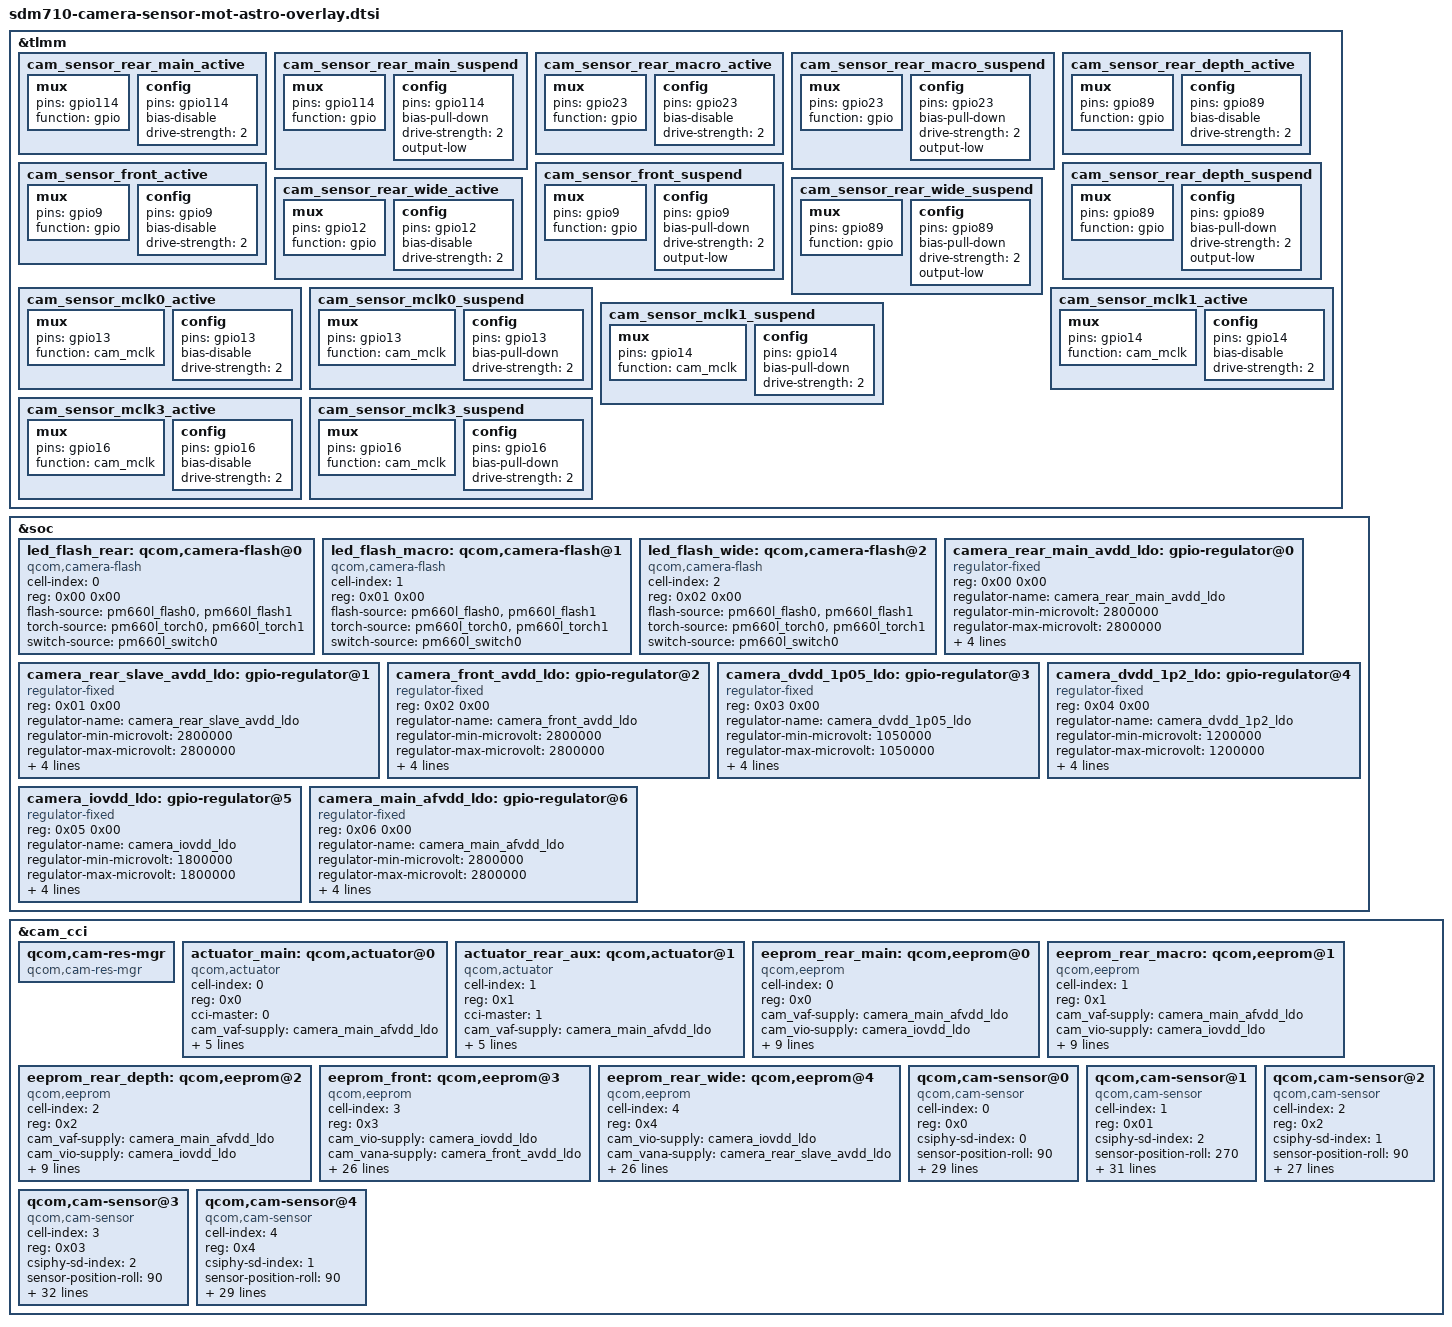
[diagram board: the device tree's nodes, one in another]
/*
 * Copyright (c) 2016-2018, The Linux Foundation. All rights reserved.
 *
 * This program is free software; you can redistribute it and/or modify
 * it under the terms of the GNU General Public License version 2 and
 * only version 2 as published by the Free Software Foundation.
 *
 * This program is distributed in the hope that it will be useful,
 * but WITHOUT ANY WARRANTY; without even the implied warranty of
 * MERCHANTABILITY or FITNESS FOR A PARTICULAR PURPOSE.  See the
 * GNU General Public License for more details.
 */

&tlmm {
	/*REAR_MAIN:CAM0_RST_N*/
	cam_sensor_rear_main_active: cam_sensor_rear_main_active {
		/* MAIN RESET active*/
		mux {
			pins = "gpio114";
			function = "gpio";
		};

		config {
			pins = "gpio114";
			bias-disable; /* No PULL */
			drive-strength = <2>; /* 2 MA */
		};
	};

	cam_sensor_rear_main_suspend: cam_sensor_rear_main_suspend {
		/* MAIN RESET suspend*/
		mux {
			pins = "gpio114";
			function = "gpio";
		};

		config {
			pins = "gpio114";
			bias-pull-down; /* PULL DOWN */
			drive-strength = <2>; /* 2 MA */
			output-low;
		};
	};
	/*MACRO:CAM1_RST_N*/
	cam_sensor_rear_macro_active: cam_sensor_rear_macro_active {
		/* MACRO RESET active*/
		mux {
			pins = "gpio23";
			function = "gpio";
		};

		config {
			pins = "gpio23";
			bias-disable; /* No PULL */
			drive-strength = <2>; /* 2 MA */
		};
	};

	cam_sensor_rear_macro_suspend: cam_sensor_rear_macro_suspend {
		/* MAIN RESET suspend*/
		mux {
			pins = "gpio23";
			function = "gpio";
		};

		config {
			pins = "gpio23";
			bias-pull-down; /* PULL DOWN */
			drive-strength = <2>; /* 2 MA */
			output-low;
		};
	};

/*depth:CAM3_RST_N*/
	cam_sensor_rear_depth_active: cam_sensor_rear_depth_active {
		/* MACRO RESET active*/
		mux {
			pins = "gpio89";
			function = "gpio";
		};

		config {
			pins = "gpio89";
			bias-disable; /* No PULL */
			drive-strength = <2>; /* 2 MA */
		};
	};

	cam_sensor_rear_depth_suspend: cam_sensor_rear_depth_suspend {
		/* MAIN RESET suspend*/
		mux {
			pins = "gpio89";
			function = "gpio";
		};

		config {
			pins = "gpio89";
			bias-pull-down; /* PULL DOWN */
			drive-strength = <2>; /* 2 MA */
			output-low;
		};
	};

/*front s5k4h7 CAM2_RST_N*/
 cam_sensor_front_active: cam_sensor_front_active {
		/* MACRO RESET active*/
		mux {
			pins = "gpio9";
			function = "gpio";
		};

		config {
			pins = "gpio9";
			bias-disable; /* No PULL */
			drive-strength = <2>; /* 2 MA */
		};
	};

	cam_sensor_front_suspend: cam_sensor_front_suspend {
		/* MAIN RESET suspend*/
		mux {
			pins = "gpio9";
			function = "gpio";
		};

		config {
			pins = "gpio9";
			bias-pull-down; /* PULL DOWN */
			drive-strength = <2>; /* 2 MA */
			output-low;
		};
	};
/*rear wide s5k4h7 CAM4_RST_N */
cam_sensor_rear_wide_active: cam_sensor_rear_wide_active {
		/* MACRO RESET active*/
		mux {
			pins = "gpio12";
			function = "gpio";
		};

		config {
			pins = "gpio12";
			bias-disable; /* No PULL */
			drive-strength = <2>; /* 2 MA */
		};
	};

	cam_sensor_rear_wide_suspend: cam_sensor_rear_wide_suspend {
		/* MAIN RESET suspend*/
		mux {
			pins = "gpio89";
			function = "gpio";
		};

		config {
			pins = "gpio89";
			bias-pull-down; /* PULL DOWN */
			drive-strength = <2>; /* 2 MA */
			output-low;
		};
	};

	cam_sensor_mclk0_active: cam_sensor_mclk0_active {
		/* MCLK0 */
		mux {
			pins = "gpio13";
			function = "cam_mclk";
		};

		config {
			pins = "gpio13";
			bias-disable; /* No PULL */
			drive-strength = <2>; /* 2 MA */
		};
	};

	cam_sensor_mclk0_suspend: cam_sensor_mclk0_suspend {
		/* MCLK0 */
		mux {
			pins = "gpio13";
			function = "cam_mclk";
		};

		config {
			pins = "gpio13";
			bias-pull-down; /* PULL DOWN */
			drive-strength = <2>; /* 2 MA */
		};
	};

	cam_sensor_mclk1_active: cam_sensor_mclk1_active {
		/* MCLK1 */
		mux {
			pins = "gpio14";
			function = "cam_mclk";
		};

		config {
			pins = "gpio14";
			bias-disable; /* No PULL */
			drive-strength = <2>; /* 2 MA */
		};
	};

	cam_sensor_mclk1_suspend: cam_sensor_mclk1_suspend {
		/* MCLK0 */
		mux {
			pins = "gpio14";
			function = "cam_mclk";
		};

		config {
			pins = "gpio14";
			bias-pull-down; /* PULL DOWN */
			drive-strength = <2>; /* 2 MA */
		};
	};

	cam_sensor_mclk3_active: cam_sensor_mclk3_active {
		/* MCLK1 */
		mux {
			pins = "gpio16";
			function = "cam_mclk";
		};

		config {
			pins = "gpio16";
			bias-disable; /* No PULL */
			drive-strength = <2>; /* 2 MA */
		};
	};

	cam_sensor_mclk3_suspend: cam_sensor_mclk3_suspend {
		/* MCLK0 */
		mux {
			pins = "gpio16";
			function = "cam_mclk";
		};

		config {
			pins = "gpio16";
			bias-pull-down; /* PULL DOWN */
			drive-strength = <2>; /* 2 MA */
		};
	};
};

&soc {
	led_flash_rear: qcom,camera-flash@0 {
		cell-index = <0>;
		reg = <0x00 0x00>;
		compatible = "qcom,camera-flash";
		flash-source = <&pm660l_flash0 &pm660l_flash1>;
		torch-source = <&pm660l_torch0 &pm660l_torch1>;
		switch-source = <&pm660l_switch0>;
		status = "ok";
	};
	led_flash_macro: qcom,camera-flash@1 {
		cell-index = <1>;
		reg = <0x01 0x00>;
		compatible = "qcom,camera-flash";
		flash-source = <&pm660l_flash0 &pm660l_flash1>;
		torch-source = <&pm660l_torch0 &pm660l_torch1>;
		switch-source = <&pm660l_switch0>;
		status = "ok";
	};
	led_flash_wide: qcom,camera-flash@2 {
		cell-index = <2>;
		reg = <0x02 0x00>;
		compatible = "qcom,camera-flash";
		flash-source = <&pm660l_flash0 &pm660l_flash1>;
		torch-source = <&pm660l_torch0 &pm660l_torch1>;
		switch-source = <&pm660l_switch0>;
		status = "ok";
	};
	/*avdd*/
	camera_rear_main_avdd_ldo: gpio-regulator@0 {
		compatible = "regulator-fixed";
		reg = <0x00 0x00>;
		regulator-name = "camera_rear_main_avdd_ldo";
		regulator-min-microvolt = <2800000>;
		regulator-max-microvolt = <2800000>;
		regulator-enable-ramp-delay = <233>;
		enable-active-high;
		gpio = <&tlmm 11 0>;
		vin-supply = <&pm660l_bob>;
	};

	camera_rear_slave_avdd_ldo: gpio-regulator@1 {
		compatible = "regulator-fixed";
		reg = <0x01 0x00>;
		regulator-name = "camera_rear_slave_avdd_ldo";
		regulator-min-microvolt = <2800000>;
		regulator-max-microvolt = <2800000>;
		regulator-enable-ramp-delay = <233>;
		enable-active-high;
		gpio = <&tlmm 76 0>;
		vin-supply = <&pm660l_bob>;
	};
	camera_front_avdd_ldo: gpio-regulator@2 {
		compatible = "regulator-fixed";
		reg = <0x02 0x00>;
		regulator-name = "camera_front_avdd_ldo";
		regulator-min-microvolt = <2800000>;
		regulator-max-microvolt = <2800000>;
		regulator-enable-ramp-delay = <233>;
		enable-active-high;
		gpio = <&tlmm 77 0>;
		vin-supply = <&pm660l_bob>;
	};
	/*dvdd*/
	camera_dvdd_1p05_ldo: gpio-regulator@3 {
		compatible = "regulator-fixed";
		reg = <0x03 0x00>;
		regulator-name = "camera_dvdd_1p05_ldo";
		regulator-min-microvolt = <1050000>;
		regulator-max-microvolt = <1050000>;
		regulator-enable-ramp-delay = <233>;
		enable-active-high;
		gpio = <&tlmm 21 0>;
		vin-supply = <&pm660_s6>;
	};
	camera_dvdd_1p2_ldo: gpio-regulator@4 {
		compatible = "regulator-fixed";
		reg = <0x04 0x00>;
		regulator-name = "camera_dvdd_1p2_ldo";
		regulator-min-microvolt = <1200000>;
		regulator-max-microvolt = <1200000>;
		regulator-enable-ramp-delay = <233>;
		enable-active-high;
		gpio = <&pm660l_gpios 4 0>;
		vin-supply = <&pm660_s6>;
	};

//dovdd
	camera_iovdd_ldo: gpio-regulator@5 {
		compatible = "regulator-fixed";
		reg = <0x05 0x00>;
		regulator-name = "camera_iovdd_ldo";
		regulator-min-microvolt = <1800000>;
		regulator-max-microvolt = <1800000>;
		regulator-enable-ramp-delay = <233>;
		enable-active-high;
		gpio = <&tlmm 143 0>;
		vin-supply = <&pm660_s4>;
	};

//actuator:
	camera_main_afvdd_ldo: gpio-regulator@6 {
		compatible = "regulator-fixed";
		reg = <0x06 0x00>;
		regulator-name = "camera_main_afvdd_ldo";
		regulator-min-microvolt = <2800000>;
		regulator-max-microvolt = <2800000>;
		regulator-enable-ramp-delay = <233>;
		enable-active-high;
		gpio = <&tlmm 26 0>;
		vin-supply = <&pm660l_bob>;
	};
};

&cam_cci {
	qcom,cam-res-mgr {
		compatible = "qcom,cam-res-mgr";
		status = "ok";
    };
	actuator_main: qcom,actuator@0 {
		cell-index = <0>;
		reg = <0x0>;
		compatible = "qcom,actuator";
		cci-master = <0>;
		cam_vaf-supply = <&camera_main_afvdd_ldo>;
		regulator-names = "cam_vaf";
		rgltr-cntrl-support;
		rgltr-min-voltage = <2800000>;
		rgltr-max-voltage = <2800000>;
		rgltr-load-current = <0>;
	};
	actuator_rear_aux: qcom,actuator@1 {
		cell-index = <1>;
		reg = <0x1>;
		compatible = "qcom,actuator";
		cci-master = <1>;
		cam_vaf-supply = <&camera_main_afvdd_ldo>;
		regulator-names = "cam_vaf";
		rgltr-cntrl-support;
		rgltr-min-voltage = <2800000>;
		rgltr-max-voltage = <2800000>;
		rgltr-load-current = <0>;
	};
//eeprom for s5kgm1
	eeprom_rear_main: qcom,eeprom@0 {
		cell-index = <0>;
		reg = <0x0>;
		compatible = "qcom,eeprom";
		cam_vaf-supply = <&camera_main_afvdd_ldo>;
		cam_vio-supply = <&camera_iovdd_ldo>;
		regulator-names = "cam_vaf", "cam_vio";
		rgltr-cntrl-support;
		rgltr-min-voltage = <2800000 1800000>;
		rgltr-max-voltage = <2800000 1800000>;
		rgltr-load-current = <0 0>;
		cci-master = <0>;
		status = "ok";
		clocks = <&clock_camcc CAM_CC_MCLK0_CLK>;
		clock-names = "cam_clk";
		clock-cntl-level = "turbo";
		clock-rates = <24000000>;
	};
//eeprom for s5k5e9
	eeprom_rear_macro: qcom,eeprom@1 {
		cell-index = <1>;
		reg = <0x1>;
		compatible = "qcom,eeprom";
		cam_vaf-supply = <&camera_main_afvdd_ldo>;
		cam_vio-supply = <&camera_iovdd_ldo>;
		regulator-names = "cam_vaf", "cam_vio";
		rgltr-cntrl-support;
		rgltr-min-voltage = <2800000 1800000>;
		rgltr-max-voltage = <2800000 1800000>;
		rgltr-load-current = <0 0>;
		cci-master = <1>;
		status = "ok";
		clocks = <&clock_camcc CAM_CC_MCLK1_CLK>;
		clock-names = "cam_clk";
		clock-cntl-level = "turbo";
		clock-rates = <24000000>;
	};
//eeprom for ov2180
	eeprom_rear_depth: qcom,eeprom@2 {
		cell-index = <2>;
		reg = <0x2>;
		compatible = "qcom,eeprom";
		cam_vaf-supply = <&camera_main_afvdd_ldo>;
		cam_vio-supply = <&camera_iovdd_ldo>;
		regulator-names = "cam_vaf", "cam_vio";
		rgltr-cntrl-support;
		rgltr-min-voltage = <2800000 1800000>;
		rgltr-max-voltage = <2800000 1800000>;
		rgltr-load-current = <0 0>;
		cci-master = <1>;
		status = "ok";
		clocks = <&clock_camcc CAM_CC_MCLK1_CLK>;
		clock-names = "cam_clk";
		clock-cntl-level = "turbo";
		clock-rates = <24000000>;
	};
//eeprom for front s5k4h7
	eeprom_front: qcom,eeprom@3 {
		cell-index = <3>;
		reg = <0x3>;
		compatible = "qcom,eeprom";
		cam_vio-supply = <&camera_iovdd_ldo>;
		cam_vana-supply = <&camera_front_avdd_ldo>;
		cam_vdig-supply = <&camera_dvdd_1p2_ldo>;
		cam_clk-supply = <&titan_top_gdsc>;
		regulator-names = "cam_vio", "cam_vana", "cam_vdig",
			"cam_clk";
		rgltr-cntrl-support;
		rgltr-min-voltage = <1800000 2800000 1200000 0>;
		rgltr-max-voltage = <1800000 2800000 1200000 0>;
		rgltr-load-current = <0 80000 120000 0>;
		gpio-no-mux = <0>;
		pinctrl-names = "cam_default", "cam_suspend";
		pinctrl-0 = <&cam_sensor_mclk3_active
				 &cam_sensor_front_active>;
		pinctrl-1 = <&cam_sensor_mclk3_suspend
				 &cam_sensor_front_suspend>;
		gpios = <&tlmm 16 0>,
				<&tlmm 9  0>,
				<&tlmm 24 0>,
				<&tlmm 25 0>;
		gpio-reset = <1>;
		gpio-custom1 = <2>;
		gpio-custom2 = <3>;
		gpio-req-tbl-num = <0 1 2 3>;
		gpio-req-tbl-flags = <1 0 0 0>;
		gpio-req-tbl-label = "CAMIF_MCLK3",
			"CAM_RESET2","CAM_GPIO_EN","CAM_GPIO_SEL";
		sensor-mode = <0>;
		cci-master = <0>;
		status = "ok";
		clocks = <&clock_camcc CAM_CC_MCLK3_CLK>;
		clock-names = "cam_clk";
		clock-cntl-level = "turbo";
		clock-rates = <24000000>;
	};
//eeprom for rear s5k4h7
	eeprom_rear_wide: qcom,eeprom@4 {
		cell-index = <4>;
		reg = <0x4>;
		compatible = "qcom,eeprom";
		cam_vio-supply = <&camera_iovdd_ldo>;
		cam_vana-supply = <&camera_rear_slave_avdd_ldo>;
		cam_vdig-supply = <&camera_dvdd_1p2_ldo>;
		cam_clk-supply = <&titan_top_gdsc>;
		regulator-names = "cam_vio", "cam_vana", "cam_vdig",
			"cam_clk";
		rgltr-cntrl-support;
		rgltr-min-voltage = <1800000 2800000 1200000 0>;
		rgltr-max-voltage = <1800000 2800000 1200000 0>;
		rgltr-load-current = <0 80000 120000 0>;
		gpio-no-mux = <0>;
		pinctrl-names = "cam_default", "cam_suspend";
		pinctrl-0 = <&cam_sensor_mclk3_active
				 &cam_sensor_rear_wide_active>;
		pinctrl-1 = <&cam_sensor_mclk3_suspend
				 &cam_sensor_rear_wide_suspend>;
		gpios = <&tlmm 16 0>,
				<&tlmm 12 0>,
				<&tlmm 24 0>,
				<&tlmm 25 0>;
		gpio-reset = <1>;
		gpio-custom1 = <2>;
		gpio-custom2 = <3>;
		gpio-req-tbl-num = <0 1 2 3>;
		gpio-req-tbl-flags = <1 0 0 0>;
		gpio-req-tbl-label = "CAMIF_MCLK3",
			"CAM_RESET4","CAM_GPIO_EN","CAM_GPIO_SEL";
		sensor-mode = <0>;
		cci-master = <1>;
		status = "ok";
		clocks = <&clock_camcc CAM_CC_MCLK3_CLK>;
		clock-names = "cam_clk";
		clock-cntl-level = "turbo";
		clock-rates = <24000000>;
	};

	qcom,cam-sensor@0 {
		cell-index = <0>;
		compatible = "qcom,cam-sensor";
		reg = <0x0>;
		csiphy-sd-index = <0>;
		sensor-position-roll = <90>;
		sensor-position-pitch = <0>;
		sensor-position-yaw = <180>;
		led-flash-src = <&led_flash_rear>;
		actuator-src = <&actuator_main>;
		eeprom-src = <&eeprom_rear_main>;
		cam_vio-supply = <&camera_iovdd_ldo>;
		cam_vana-supply = <&camera_rear_main_avdd_ldo>;
		cam_vdig-supply = <&camera_dvdd_1p05_ldo>;
		cam_clk-supply = <&titan_top_gdsc>;
		regulator-names = "cam_vio", "cam_vana", "cam_vdig", "cam_clk";
		rgltr-cntrl-support;
		rgltr-min-voltage = <1800000 2800000 1050000 0>;
		rgltr-max-voltage = <1800000 2800000 1050000 0>;
		rgltr-load-current = <0 80000 105000 0>;
		gpio-no-mux = <0>;
		pinctrl-names = "cam_default", "cam_suspend";
		pinctrl-0 = <&cam_sensor_mclk0_active
				&cam_sensor_rear_main_active>;
		pinctrl-1 = <&cam_sensor_mclk0_suspend
				&cam_sensor_rear_main_suspend>;
		gpios = <&tlmm 13 0>,
			<&tlmm 114 0>;
		gpio-reset = <1>;
		gpio-req-tbl-num = <0 1>;
		gpio-req-tbl-flags = <1 0>;
		gpio-req-tbl-label = "CAMIF_MCLK0",
					"CAM_RESET0";
		cci-master = <0>;
		status = "ok";
		clocks = <&clock_camcc CAM_CC_MCLK0_CLK>;
		clock-names = "cam_clk";
		clock-cntl-level = "turbo";
		clock-rates = <24000000>;
	};

/*8M s5k4h7  front*/
	qcom,cam-sensor@1 {
		cell-index = <1>;
		compatible = "qcom,cam-sensor";
		reg = <0x01>;
		csiphy-sd-index = <2>;
		sensor-position-roll = <270>;
		sensor-position-pitch = <0>;
		sensor-position-yaw = <0>;
		eeprom-src = <&eeprom_front>;
		cam_vio-supply = <&camera_iovdd_ldo>;
		cam_vana-supply = <&camera_front_avdd_ldo>;
		cam_vdig-supply = <&camera_dvdd_1p2_ldo>;
		cam_clk-supply = <&titan_top_gdsc>;
		regulator-names = "cam_vio", "cam_vana", "cam_vdig",
			"cam_clk";
		rgltr-cntrl-support;
		rgltr-min-voltage = <1800000 2800000 1200000 0>;
		rgltr-max-voltage = <1800000 2800000 1200000 0>;
		rgltr-load-current = <0 80000 120000 0>;
		gpio-no-mux = <0>;
		pinctrl-names = "cam_default", "cam_suspend";
		pinctrl-0 = <&cam_sensor_mclk3_active
				 &cam_sensor_front_active>;
		pinctrl-1 = <&cam_sensor_mclk3_suspend
				 &cam_sensor_front_suspend>;
		gpios = <&tlmm 16 0>,
				<&tlmm 9  0>,
				<&tlmm 24 0>,
				<&tlmm 25 0>;
		gpio-reset = <1>;
		gpio-custom1 = <2>;
		gpio-custom2 = <3>;
		gpio-req-tbl-num = <0 1 2 3>;
		gpio-req-tbl-flags = <1 0 0 0>;
		gpio-req-tbl-label = "CAMIF_MCLK3",
			"CAM_RESET2","CAM_GPIO_EN","CAM_GPIO_SEL";
		sensor-mode = <0>;
		cci-master = <0>;
		status = "ok";
		clocks = <&clock_camcc CAM_CC_MCLK3_CLK>;
		clock-names = "cam_clk";
		clock-cntl-level = "turbo";
		clock-rates = <24000000>;
	};

/*ov2180*/
	qcom,cam-sensor@2 {
		cell-index = <2>;
		compatible = "qcom,cam-sensor";
		reg = <0x2>;
		csiphy-sd-index = <1>;
		sensor-position-roll = <90>;
		sensor-position-pitch = <0>;
		sensor-position-yaw = <180>;
		eeprom-src = <&eeprom_rear_depth>;
		cam_vio-supply = <&camera_iovdd_ldo>;
		cam_vana-supply = <&camera_rear_slave_avdd_ldo>;
		cam_vdig-supply = <&camera_dvdd_1p2_ldo>;
		cam_clk-supply = <&titan_top_gdsc>;
		regulator-names = "cam_vio", "cam_vana", "cam_vdig", "cam_clk";
		rgltr-cntrl-support;
		rgltr-min-voltage = <1800000 2800000 1200000 0>;
		rgltr-max-voltage = <1800000 2800000 1200000 0>;
		rgltr-load-current = <0 80000 120000 0>;
		gpio-no-mux = <0>;
		pinctrl-names = "cam_default", "cam_suspend";
		pinctrl-0 = <&cam_sensor_mclk1_active
				&cam_sensor_rear_depth_active>;
		pinctrl-1 = <&cam_sensor_mclk1_suspend
				&cam_sensor_rear_depth_suspend>;
		gpios = <&tlmm 14 0>,
			<&tlmm 89 0>;
		gpio-reset = <1>;
		gpio-req-tbl-num = <0 1>;
		gpio-req-tbl-flags = <1 0>;
		gpio-req-tbl-label = "CAMIF_MCLK1",
					"CAM_RESET3";
		cci-master = <1>;
		status = "ok";
		clocks = <&clock_camcc CAM_CC_MCLK1_CLK>;
		clock-names = "cam_clk";
		clock-cntl-level = "turbo";
		clock-rates = <24000000>;
	};

/*8M S5K4H7Y qtech rear aux*/
	qcom,cam-sensor@3 {
		cell-index = <3>;
		compatible = "qcom,cam-sensor";
		reg = <0x03>;
		csiphy-sd-index = <2>;
		sensor-position-roll = <90>;
		sensor-position-pitch = <0>;
		sensor-position-yaw = <180>;
		led-flash-src = <&led_flash_wide>;
		eeprom-src = <&eeprom_rear_wide>;
		cam_vio-supply = <&camera_iovdd_ldo>;
		cam_vana-supply = <&camera_rear_slave_avdd_ldo>;
		cam_vdig-supply = <&camera_dvdd_1p2_ldo>;
		cam_clk-supply = <&titan_top_gdsc>;
		regulator-names = "cam_vio", "cam_vana", "cam_vdig",
			"cam_clk";
		rgltr-cntrl-support;
		rgltr-min-voltage = <1800000 2800000 1200000 0>;
		rgltr-max-voltage = <1800000 2800000 1200000 0>;
		rgltr-load-current = <0 80000 120000 0>;
		gpio-no-mux = <0>;
		pinctrl-names = "cam_default", "cam_suspend";
		pinctrl-0 = <&cam_sensor_mclk3_active
				 &cam_sensor_rear_wide_active>;
		pinctrl-1 = <&cam_sensor_mclk3_suspend
				 &cam_sensor_rear_wide_suspend>;
		gpios = <&tlmm 16 0>,
				<&tlmm 12 0>,
				<&tlmm 24 0>,
				<&tlmm 25 0>;
		gpio-reset = <1>;
		gpio-custom1 = <2>;
		gpio-custom2 = <3>;
		gpio-req-tbl-num = <0 1 2 3>;
		gpio-req-tbl-flags = <1 0 0 0>;
		gpio-req-tbl-label = "CAMIF_MCLK3",
			"CAM_RESET4","CAM_GPIO_EN","CAM_GPIO_SEL";
		sensor-mode = <0>;
		cci-master = <1>;
		status = "ok";
		clocks = <&clock_camcc CAM_CC_MCLK3_CLK>;
		clock-names = "cam_clk";
		clock-cntl-level = "turbo";
		clock-rates = <24000000>;
	};

/*s5k5e9*/
	qcom,cam-sensor@4 {
		cell-index = <4>;
		compatible = "qcom,cam-sensor";
		reg = <0x4>;
		csiphy-sd-index = <1>;
		sensor-position-roll = <90>;
		sensor-position-pitch = <0>;
		sensor-position-yaw = <180>;
		led-flash-src = <&led_flash_macro>;
		actuator-src = <&actuator_rear_aux>;
		eeprom-src = <&eeprom_rear_macro>;
		cam_vio-supply = <&camera_iovdd_ldo>;
		cam_vana-supply = <&camera_rear_slave_avdd_ldo>;
		cam_vdig-supply = <&camera_dvdd_1p2_ldo>;
		cam_clk-supply = <&titan_top_gdsc>;
		regulator-names = "cam_vio", "cam_vana", "cam_vdig", "cam_clk";
		rgltr-cntrl-support;
		rgltr-min-voltage = <1800000 2800000 1200000 0>;
		rgltr-max-voltage = <1800000 2800000 1200000 0>;
		rgltr-load-current = <0 80000 120000 0>;
		gpio-no-mux = <0>;
		pinctrl-names = "cam_default", "cam_suspend";
		pinctrl-0 = <&cam_sensor_mclk1_active
				&cam_sensor_rear_macro_active>;
		pinctrl-1 = <&cam_sensor_mclk1_suspend
				&cam_sensor_rear_macro_suspend>;
		gpios = <&tlmm 14 0>,
			<&tlmm 23 0>;
		gpio-reset = <1>;
		gpio-req-tbl-num = <0 1>;
		gpio-req-tbl-flags = <1 0>;
		gpio-req-tbl-label = "CAMIF_MCLK1",
					"CAM_RESET1";
		cci-master = <1>;
		status = "ok";
		clocks = <&clock_camcc CAM_CC_MCLK1_CLK>;
		clock-names = "cam_clk";
		clock-cntl-level = "turbo";
		clock-rates = <24000000>;
	};

};
